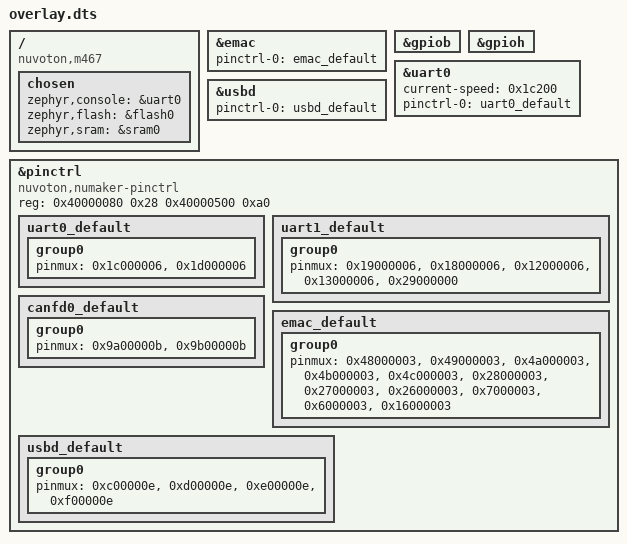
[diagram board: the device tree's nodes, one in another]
/ {
	compatible = "nuvoton,m467", "nuvoton,pfm-m467";
	chosen {
		zephyr,console = &uart0;
		zephyr,flash = &flash0;
		zephyr,sram = &sram0;
	};
};
&emac{
	status = "okay";
	pinctrl-0 = < &emac_default >;
	pinctrl-names = "default";
};
&gpiob{
	status = "okay";
};
&gpioh{
	status = "okay";
};
&uart0{
	status = "okay";
	current-speed = < 0x1c200 >;
	pinctrl-0 = < &uart0_default >;
	pinctrl-names = "default";
};
&usbd{
	status = "okay";
	pinctrl-0 = < &usbd_default >;
	pinctrl-names = "default";
};
&pinctrl{
	compatible = "nuvoton,numaker-pinctrl";
	reg = < 0x40000080 0x28 0x40000500 0xa0 >;
	reg-names = "mfos", "mfp";
	status = "okay";
	uart0_default: uart0_default {
		group0 {
			pinmux = < 0x1c000006 >, < 0x1d000006 >;
		};
	};
	uart1_default: uart1_default {
		group0 {
			pinmux = < 0x19000006 >, < 0x18000006 >, < 0x12000006 >, < 0x13000006 >, < 0x29000000 >;
		};
	};
	canfd0_default: canfd0_default {
		group0 {
			pinmux = < 0x9a00000b >, < 0x9b00000b >;
		};
	};
	emac_default: emac_default {
		group0 {
			pinmux = < 0x48000003 >, < 0x49000003 >, < 0x4a000003 >, < 0x4b000003 >, < 0x4c000003 >, < 0x28000003 >, < 0x27000003 >, < 0x26000003 >, < 0x7000003 >, < 0x6000003 >, < 0x16000003 >;
		};
	};
	usbd_default: usbd_default {
		group0 {
			pinmux = < 0xc00000e >, < 0xd00000e >, < 0xe00000e >, < 0xf00000e >;
		};
	};
};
